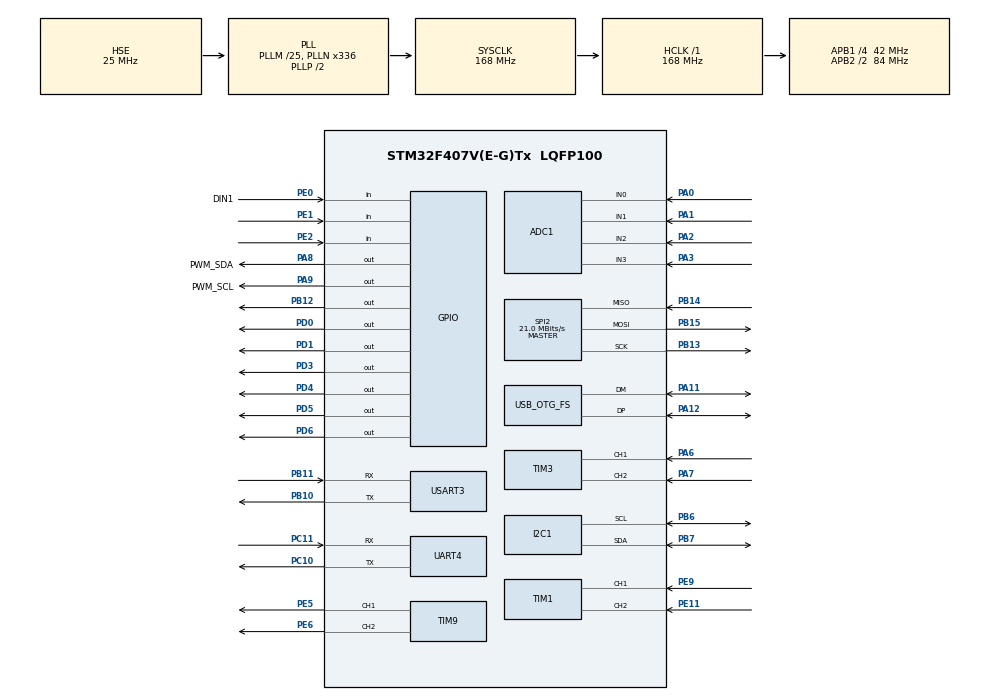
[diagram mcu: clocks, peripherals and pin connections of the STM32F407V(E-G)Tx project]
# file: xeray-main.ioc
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ADC1.Channel-0\#ChannelRegularConversion=ADC_CHANNEL_0
ADC1.NbrOfConversionFlag=1
ADC1.Rank-0\#ChannelRegularConversion=1
ADC1.SamplingTime-0\#ChannelRegularConversion=ADC_SAMPLETIME_3CYCLES
ADC1.master=1
Mcu.Family=STM32F4
Mcu.Name=STM32F407V(E-G)Tx
Mcu.Package=LQFP100
NVIC.PriorityGroup=NVIC_PRIORITYGROUP_4
PA0-WKUP.Signal=ADCx_IN0
PA1.Signal=ADCx_IN1
PA11.Mode=Device_Only
PA11.Signal=USB_OTG_FS_DM
PA12.Mode=Device_Only
PA12.Signal=USB_OTG_FS_DP
PA13.Mode=Serial_Wire
PA13.Signal=SYS_JTMS-SWDIO
PA14.Mode=Serial_Wire
PA14.Signal=SYS_JTCK-SWCLK
PA2.Signal=ADCx_IN2
PA3.Signal=ADCx_IN3
PA6.Signal=S_TIM3_CH1
PA7.Signal=S_TIM3_CH2
PA8.GPIO_Label=PWM_SDA
PA8.GPIO_ModeDefaultOutputPP=GPIO_MODE_OUTPUT_OD
PA8.GPIO_PinState=GPIO_PIN_SET
PA8.GPIO_Speed=GPIO_SPEED_FREQ_LOW
PA8.Signal=GPIO_Output
PA9.GPIO_Label=PWM_SCL
PA9.GPIO_ModeDefaultOutputPP=GPIO_MODE_OUTPUT_OD
PA9.GPIO_PinState=GPIO_PIN_SET
PA9.GPIO_Speed=GPIO_SPEED_FREQ_LOW
PA9.Signal=GPIO_Output
PB10.Mode=Asynchronous
PB10.Signal=USART3_TX
PB11.Mode=Asynchronous
PB11.Signal=USART3_RX
PB12.Signal=GPIO_Output
PB13.Mode=Full_Duplex_Master
PB13.Signal=SPI2_SCK
PB14.Mode=Full_Duplex_Master
PB14.Signal=SPI2_MISO
PB15.Mode=Full_Duplex_Master
PB15.Signal=SPI2_MOSI
PB6.Mode=I2C
PB6.Signal=I2C1_SCL
PB7.Mode=I2C
PB7.Signal=I2C1_SDA
PC10.Mode=Asynchronous
PC10.Signal=UART4_TX
PC11.Mode=Asynchronous
PC11.Signal=UART4_RX
PD0.Signal=GPIO_Output
PD1.Signal=GPIO_Output
PD3.Signal=GPIO_Output
PD4.Signal=GPIO_Output
PD5.Signal=GPIO_Output
PD6.Signal=GPIO_Output
PE0.GPIO_Label=DIN1
PE0.Signal=GPIO_Input
PE1.Signal=GPIO_Input
PE11.Signal=S_TIM1_CH2
PE2.Signal=GPIO_Input
PE5.Signal=S_TIM9_CH1
PE6.Signal=S_TIM9_CH2
PE9.Signal=S_TIM1_CH1
PH0-OSC_IN.Mode=HSE-External-Oscillator
PH0-OSC_IN.Signal=RCC_OSC_IN
PH1-OSC_OUT.Mode=HSE-External-Oscillator
PH1-OSC_OUT.Signal=RCC_OSC_OUT
ProjectManager.HeapSize=0x200
ProjectManager.StackSize=0x400
ProjectManager.TargetToolchain=STM32CubeIDE
RCC.48MHZClocksFreq_Value=48000000
RCC.AHBFreq_Value=168000000
RCC.APB1CLKDivider=RCC_HCLK_DIV4
RCC.APB1Freq_Value=42000000
RCC.APB1TimFreq_Value=84000000
RCC.APB2CLKDivider=RCC_HCLK_DIV2
RCC.APB2Freq_Value=84000000
RCC.APB2TimFreq_Value=168000000
RCC.CortexFreq_Value=168000000
RCC.HCLKFreq_Value=168000000
RCC.HSE_VALUE=25000000
RCC.HSI_VALUE=16000000
RCC.LSE_VALUE=32768
RCC.PLLM=25
RCC.PLLN=336
RCC.PLLQ=7
RCC.SYSCLKFreq_VALUE=168000000
RCC.SYSCLKSource=RCC_SYSCLKSOURCE_PLLCLK
RCC.VCOOutputFreq_Value=336000000
SH.ADCx_IN0.0=ADC1_IN0,IN0
SH.ADCx_IN1.0=ADC1_IN1,IN1
SH.ADCx_IN2.0=ADC1_IN2,IN2
SH.ADCx_IN3.0=ADC1_IN3,IN3
SH.S_TIM1_CH1.0=TIM1_CH1,Encoder_Interface
SH.S_TIM1_CH2.0=TIM1_CH2,Encoder_Interface
SH.S_TIM3_CH1.0=TIM3_CH1,Encoder_Interface
SH.S_TIM3_CH2.0=TIM3_CH2,Encoder_Interface
SH.S_TIM9_CH1.0=TIM9_CH1,PWM Generation1 CH1
SH.S_TIM9_CH2.0=TIM9_CH2,PWM Generation2 CH2
SPI2.BaudRatePrescaler=SPI_BAUDRATEPRESCALER_2
SPI2.CalculateBaudRate=21.0 MBits/s
SPI2.Direction=SPI_DIRECTION_2LINES
SPI2.Mode=SPI_MODE_MASTER
SPI2.VirtualType=VM_MASTER
TIM9.Channel-PWM\ Generation1\ CH1=TIM_CHANNEL_1
TIM9.Channel-PWM\ Generation2\ CH2=TIM_CHANNEL_2
UART4.VirtualMode=Asynchronous
USART3.VirtualMode=VM_ASYNC
USB_OTG_FS.VirtualMode=Device_Only
board=custom

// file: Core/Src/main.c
/* USER CODE BEGIN Header */
/**
  ******************************************************************************
  * @file           : main.c
  * @brief          : Main program body
  ******************************************************************************
  * @attention
  *
  * Copyright (c) 2026 STMicroelectronics.
  * All rights reserved.
  *
  * This software is licensed under terms that can be found in the LICENSE file
  * in the root directory of this software component.
  * If no LICENSE file comes with this software, it is provided AS-IS.
  *
  ******************************************************************************
  */
/* USER CODE END Header */
#include "main.h"

/* USER CODE BEGIN Includes */
#include "din1_link.h"
/* USER CODE END Includes */

ADC_HandleTypeDef hadc1;

I2C_HandleTypeDef hi2c1;

SPI_HandleTypeDef hspi2;

TIM_HandleTypeDef htim1;
TIM_HandleTypeDef htim3;
TIM_HandleTypeDef htim9;

UART_HandleTypeDef huart4;
UART_HandleTypeDef huart3;

PCD_HandleTypeDef hpcd_USB_OTG_FS;

void SystemClock_Config(void);
static void MX_GPIO_Init(void);
static void MX_ADC1_Init(void);
static void MX_I2C1_Init(void);
static void MX_SPI2_Init(void);
static void MX_TIM1_Init(void);
static void MX_TIM3_Init(void);
static void MX_TIM9_Init(void);
static void MX_UART4_Init(void);
static void MX_USART3_UART_Init(void);
static void MX_USB_OTG_FS_PCD_Init(void);

int main(void)
{

  /* MCU Configuration--------------------------------------------------------*/

  /* Reset of all peripherals, Initializes the Flash interface and the Systick. */
  HAL_Init();

  /* Configure the system clock */
  SystemClock_Config();

  /* Initialize all configured peripherals */
  MX_GPIO_Init();
  MX_ADC1_Init();
  MX_I2C1_Init();
  MX_SPI2_Init();
  MX_TIM1_Init();
  MX_TIM3_Init();
  MX_TIM9_Init();
  MX_UART4_Init();
  MX_USART3_UART_Init();
  MX_USB_OTG_FS_PCD_Init();
  /* USER CODE BEGIN 2 */
  DIN1_Link_Init();
  /* USER CODE END 2 */

  /* Infinite loop */
  while (1)
  {

    /* USER CODE BEGIN 3 */
    DIN1_Link_Poll();
    __WFI(); /* Wake on SysTick for the next 1 ms service interval. */
  }
  /* USER CODE END 3 */
}

void SystemClock_Config(void)
{
  RCC_OscInitTypeDef RCC_OscInitStruct = {0};
  RCC_ClkInitTypeDef RCC_ClkInitStruct = {0};

  /** Configure the main internal regulator output voltage
  */
  __HAL_RCC_PWR_CLK_ENABLE();
  __HAL_PWR_VOLTAGESCALING_CONFIG(PWR_REGULATOR_VOLTAGE_SCALE1);

  /** Initializes the RCC Oscillators according to the specified parameters
  * in the RCC_OscInitTypeDef structure.
  */
  RCC_OscInitStruct.OscillatorType = RCC_OSCILLATORTYPE_HSE;
  RCC_OscInitStruct.HSEState = RCC_HSE_ON;
  RCC_OscInitStruct.PLL.PLLState = RCC_PLL_ON;
  RCC_OscInitStruct.PLL.PLLSource = RCC_PLLSOURCE_HSE;
  RCC_OscInitStruct.PLL.PLLM = 25;
  RCC_OscInitStruct.PLL.PLLN = 336;
  RCC_OscInitStruct.PLL.PLLP = RCC_PLLP_DIV2;
  RCC_OscInitStruct.PLL.PLLQ = 7;
  if (HAL_RCC_OscConfig(&RCC_OscInitStruct) != HAL_OK)
  {
    Error_Handler();
  }

  /** Initializes the CPU, AHB and APB buses clocks
  */
  RCC_ClkInitStruct.ClockType = RCC_CLOCKTYPE_HCLK|RCC_CLOCKTYPE_SYSCLK
                              |RCC_CLOCKTYPE_PCLK1|RCC_CLOCKTYPE_PCLK2;
  RCC_ClkInitStruct.SYSCLKSource = RCC_SYSCLKSOURCE_PLLCLK;
  RCC_ClkInitStruct.AHBCLKDivider = RCC_SYSCLK_DIV1;
  RCC_ClkInitStruct.APB1CLKDivider = RCC_HCLK_DIV4;
  RCC_ClkInitStruct.APB2CLKDivider = RCC_HCLK_DIV2;

  if (HAL_RCC_ClockConfig(&RCC_ClkInitStruct, FLASH_LATENCY_5) != HAL_OK)
  {
    Error_Handler();
  }
}

static void MX_ADC1_Init(void)
{

  ADC_ChannelConfTypeDef sConfig = {0};

  /** Configure the global features of the ADC (Clock, Resolution, Data Alignment and number of conversion)
  */
  hadc1.Instance = ADC1;
  hadc1.Init.ClockPrescaler = ADC_CLOCK_SYNC_PCLK_DIV4;
  hadc1.Init.Resolution = ADC_RESOLUTION_12B;
  hadc1.Init.ScanConvMode = DISABLE;
  hadc1.Init.ContinuousConvMode = DISABLE;
  hadc1.Init.DiscontinuousConvMode = DISABLE;
  hadc1.Init.ExternalTrigConvEdge = ADC_EXTERNALTRIGCONVEDGE_NONE;
  hadc1.Init.ExternalTrigConv = ADC_SOFTWARE_START;
  hadc1.Init.DataAlign = ADC_DATAALIGN_RIGHT;
  hadc1.Init.NbrOfConversion = 1;
  hadc1.Init.DMAContinuousRequests = DISABLE;
  hadc1.Init.EOCSelection = ADC_EOC_SINGLE_CONV;
  if (HAL_ADC_Init(&hadc1) != HAL_OK)
  {
    Error_Handler();
  }

  /** Configure for the selected ADC regular channel its corresponding rank in the sequencer and its sample time.
  */
  sConfig.Channel = ADC_CHANNEL_0;
  sConfig.Rank = 1;
  sConfig.SamplingTime = ADC_SAMPLETIME_3CYCLES;
  if (HAL_ADC_ConfigChannel(&hadc1, &sConfig) != HAL_OK)
  {
    Error_Handler();
  }

}

static void MX_I2C1_Init(void)
{

  hi2c1.Instance = I2C1;
  hi2c1.Init.ClockSpeed = 100000;
  hi2c1.Init.DutyCycle = I2C_DUTYCYCLE_2;
  hi2c1.Init.OwnAddress1 = 0;
  hi2c1.Init.AddressingMode = I2C_ADDRESSINGMODE_7BIT;
  hi2c1.Init.DualAddressMode = I2C_DUALADDRESS_DISABLE;
  hi2c1.Init.OwnAddress2 = 0;
  hi2c1.Init.GeneralCallMode = I2C_GENERALCALL_DISABLE;
  hi2c1.Init.NoStretchMode = I2C_NOSTRETCH_DISABLE;
  if (HAL_I2C_Init(&hi2c1) != HAL_OK)
  {
    Error_Handler();
  }

}

static void MX_SPI2_Init(void)
{

  /* SPI2 parameter configuration*/
  hspi2.Instance = SPI2;
  hspi2.Init.Mode = SPI_MODE_MASTER;
  hspi2.Init.Direction = SPI_DIRECTION_2LINES;
  hspi2.Init.DataSize = SPI_DATASIZE_8BIT;
  hspi2.Init.CLKPolarity = SPI_POLARITY_LOW;
  hspi2.Init.CLKPhase = SPI_PHASE_1EDGE;
  hspi2.Init.NSS = SPI_NSS_SOFT;
  hspi2.Init.BaudRatePrescaler = SPI_BAUDRATEPRESCALER_2;
  hspi2.Init.FirstBit = SPI_FIRSTBIT_MSB;
  hspi2.Init.TIMode = SPI_TIMODE_DISABLE;
  hspi2.Init.CRCCalculation = SPI_CRCCALCULATION_DISABLE;
  hspi2.Init.CRCPolynomial = 10;
  if (HAL_SPI_Init(&hspi2) != HAL_OK)
  {
    Error_Handler();
  }

}

static void MX_TIM1_Init(void)
{

  TIM_Encoder_InitTypeDef sConfig = {0};
  TIM_MasterConfigTypeDef sMasterConfig = {0};

  htim1.Instance = TIM1;
  htim1.Init.Prescaler = 0;
  htim1.Init.CounterMode = TIM_COUNTERMODE_UP;
  htim1.Init.Period = 65535;
  htim1.Init.ClockDivision = TIM_CLOCKDIVISION_DIV1;
  htim1.Init.RepetitionCounter = 0;
  htim1.Init.AutoReloadPreload = TIM_AUTORELOAD_PRELOAD_DISABLE;
  sConfig.EncoderMode = TIM_ENCODERMODE_TI1;
  sConfig.IC1Polarity = TIM_ICPOLARITY_RISING;
  sConfig.IC1Selection = TIM_ICSELECTION_DIRECTTI;
  sConfig.IC1Prescaler = TIM_ICPSC_DIV1;
  sConfig.IC1Filter = 0;
  sConfig.IC2Polarity = TIM_ICPOLARITY_RISING;
  sConfig.IC2Selection = TIM_ICSELECTION_DIRECTTI;
  sConfig.IC2Prescaler = TIM_ICPSC_DIV1;
  sConfig.IC2Filter = 0;
  if (HAL_TIM_Encoder_Init(&htim1, &sConfig) != HAL_OK)
  {
    Error_Handler();
  }
  sMasterConfig.MasterOutputTrigger = TIM_TRGO_RESET;
  sMasterConfig.MasterSlaveMode = TIM_MASTERSLAVEMODE_DISABLE;
  if (HAL_TIMEx_MasterConfigSynchronization(&htim1, &sMasterConfig) != HAL_OK)
  {
    Error_Handler();
  }

}

static void MX_TIM3_Init(void)
{

  TIM_Encoder_InitTypeDef sConfig = {0};
  TIM_MasterConfigTypeDef sMasterConfig = {0};

  htim3.Instance = TIM3;
  htim3.Init.Prescaler = 0;
  htim3.Init.CounterMode = TIM_COUNTERMODE_UP;
  htim3.Init.Period = 65535;
  htim3.Init.ClockDivision = TIM_CLOCKDIVISION_DIV1;
  htim3.Init.AutoReloadPreload = TIM_AUTORELOAD_PRELOAD_DISABLE;
  sConfig.EncoderMode = TIM_ENCODERMODE_TI1;
  sConfig.IC1Polarity = TIM_ICPOLARITY_RISING;
  sConfig.IC1Selection = TIM_ICSELECTION_DIRECTTI;
  sConfig.IC1Prescaler = TIM_ICPSC_DIV1;
  sConfig.IC1Filter = 0;
  sConfig.IC2Polarity = TIM_ICPOLARITY_RISING;
  sConfig.IC2Selection = TIM_ICSELECTION_DIRECTTI;
  sConfig.IC2Prescaler = TIM_ICPSC_DIV1;
  sConfig.IC2Filter = 0;
  if (HAL_TIM_Encoder_Init(&htim3, &sConfig) != HAL_OK)
  {
    Error_Handler();
  }
  sMasterConfig.MasterOutputTrigger = TIM_TRGO_RESET;
  sMasterConfig.MasterSlaveMode = TIM_MASTERSLAVEMODE_DISABLE;
  if (HAL_TIMEx_MasterConfigSynchronization(&htim3, &sMasterConfig) != HAL_OK)
  {
    Error_Handler();
  }

}

static void MX_TIM9_Init(void)
{

  TIM_OC_InitTypeDef sConfigOC = {0};

  htim9.Instance = TIM9;
  htim9.Init.Prescaler = 0;
  htim9.Init.CounterMode = TIM_COUNTERMODE_UP;
  htim9.Init.Period = 65535;
  htim9.Init.ClockDivision = TIM_CLOCKDIVISION_DIV1;
  htim9.Init.AutoReloadPreload = TIM_AUTORELOAD_PRELOAD_DISABLE;
  if (HAL_TIM_PWM_Init(&htim9) != HAL_OK)
  {
    Error_Handler();
  }
  sConfigOC.OCMode = TIM_OCMODE_PWM1;
  sConfigOC.Pulse = 0;
  sConfigOC.OCPolarity = TIM_OCPOLARITY_HIGH;
  sConfigOC.OCFastMode = TIM_OCFAST_DISABLE;
  if (HAL_TIM_PWM_ConfigChannel(&htim9, &sConfigOC, TIM_CHANNEL_1) != HAL_OK)
  {
    Error_Handler();
  }
  if (HAL_TIM_PWM_ConfigChannel(&htim9, &sConfigOC, TIM_CHANNEL_2) != HAL_OK)
  {
    Error_Handler();
  }
  HAL_TIM_MspPostInit(&htim9);

}

static void MX_UART4_Init(void)
{

  huart4.Instance = UART4;
  huart4.Init.BaudRate = 115200;
  huart4.Init.WordLength = UART_WORDLENGTH_8B;
  huart4.Init.StopBits = UART_STOPBITS_1;
  huart4.Init.Parity = UART_PARITY_NONE;
  huart4.Init.Mode = UART_MODE_TX_RX;
  huart4.Init.HwFlowCtl = UART_HWCONTROL_NONE;
  huart4.Init.OverSampling = UART_OVERSAMPLING_16;
  if (HAL_UART_Init(&huart4) != HAL_OK)
  {
    Error_Handler();
  }

}

static void MX_USART3_UART_Init(void)
{

  huart3.Instance = USART3;
  huart3.Init.BaudRate = 115200;
  huart3.Init.WordLength = UART_WORDLENGTH_8B;
  huart3.Init.StopBits = UART_STOPBITS_1;
  huart3.Init.Parity = UART_PARITY_NONE;
  huart3.Init.Mode = UART_MODE_TX_RX;
  huart3.Init.HwFlowCtl = UART_HWCONTROL_NONE;
  huart3.Init.OverSampling = UART_OVERSAMPLING_16;
  if (HAL_UART_Init(&huart3) != HAL_OK)
  {
    Error_Handler();
  }

}

static void MX_USB_OTG_FS_PCD_Init(void)
{

  hpcd_USB_OTG_FS.Instance = USB_OTG_FS;
  hpcd_USB_OTG_FS.Init.dev_endpoints = 4;
  hpcd_USB_OTG_FS.Init.speed = PCD_SPEED_FULL;
  hpcd_USB_OTG_FS.Init.dma_enable = DISABLE;
  hpcd_USB_OTG_FS.Init.phy_itface = PCD_PHY_EMBEDDED;
  hpcd_USB_OTG_FS.Init.Sof_enable = DISABLE;
  hpcd_USB_OTG_FS.Init.low_power_enable = DISABLE;
  hpcd_USB_OTG_FS.Init.lpm_enable = DISABLE;
  hpcd_USB_OTG_FS.Init.vbus_sensing_enable = DISABLE;
  hpcd_USB_OTG_FS.Init.use_dedicated_ep1 = DISABLE;
  if (HAL_PCD_Init(&hpcd_USB_OTG_FS) != HAL_OK)
  {
    Error_Handler();
  }

}

static void MX_GPIO_Init(void)
{
  GPIO_InitTypeDef GPIO_InitStruct = {0};

  /* GPIO Ports Clock Enable */
  __HAL_RCC_GPIOE_CLK_ENABLE();
  __HAL_RCC_GPIOH_CLK_ENABLE();
  __HAL_RCC_GPIOA_CLK_ENABLE();
  __HAL_RCC_GPIOB_CLK_ENABLE();
  __HAL_RCC_GPIOC_CLK_ENABLE();
  __HAL_RCC_GPIOD_CLK_ENABLE();

  /* Release software I2C before enabling the open-drain outputs. */
  HAL_GPIO_WritePin(GPIOA, PWM_SDA_Pin|PWM_SCL_Pin, GPIO_PIN_SET);

  /*Configure GPIO pin Output Level */
  HAL_GPIO_WritePin(GPIOB, GPIO_PIN_12, GPIO_PIN_RESET);

  /*Configure GPIO pin Output Level */
  HAL_GPIO_WritePin(GPIOD, GPIO_PIN_0|GPIO_PIN_1|GPIO_PIN_3|GPIO_PIN_4
                          |GPIO_PIN_5|GPIO_PIN_6, GPIO_PIN_RESET);

  /*Configure GPIO pins : PE2 PE0 PE1 */
  GPIO_InitStruct.Pin = GPIO_PIN_2|GPIO_PIN_0|GPIO_PIN_1;
  GPIO_InitStruct.Mode = GPIO_MODE_INPUT;
  GPIO_InitStruct.Pull = GPIO_NOPULL;
  HAL_GPIO_Init(GPIOE, &GPIO_InitStruct);

  /* PA8 = SDA2, PA9 = SCL2 on JP1/JP2 (software I2C). */
  GPIO_InitStruct.Pin = PWM_SDA_Pin|PWM_SCL_Pin;
  GPIO_InitStruct.Mode = GPIO_MODE_OUTPUT_OD;
  GPIO_InitStruct.Pull = GPIO_NOPULL;
  GPIO_InitStruct.Speed = GPIO_SPEED_FREQ_LOW;
  HAL_GPIO_Init(GPIOA, &GPIO_InitStruct);

  /*Configure GPIO pin : PB12 */
  GPIO_InitStruct.Pin = GPIO_PIN_12;
  GPIO_InitStruct.Mode = GPIO_MODE_OUTPUT_PP;
  GPIO_InitStruct.Pull = GPIO_NOPULL;
  GPIO_InitStruct.Speed = GPIO_SPEED_FREQ_LOW;
  HAL_GPIO_Init(GPIOB, &GPIO_InitStruct);

  /*Configure GPIO pins : PD0 PD1 PD3 PD4
                           PD5 PD6 */
  GPIO_InitStruct.Pin = GPIO_PIN_0|GPIO_PIN_1|GPIO_PIN_3|GPIO_PIN_4
                          |GPIO_PIN_5|GPIO_PIN_6;
  GPIO_InitStruct.Mode = GPIO_MODE_OUTPUT_PP;
  GPIO_InitStruct.Pull = GPIO_NOPULL;
  GPIO_InitStruct.Speed = GPIO_SPEED_FREQ_LOW;
  HAL_GPIO_Init(GPIOD, &GPIO_InitStruct);

}

void Error_Handler(void)
{
  __disable_irq();
  while (1)
  {
  }
}
